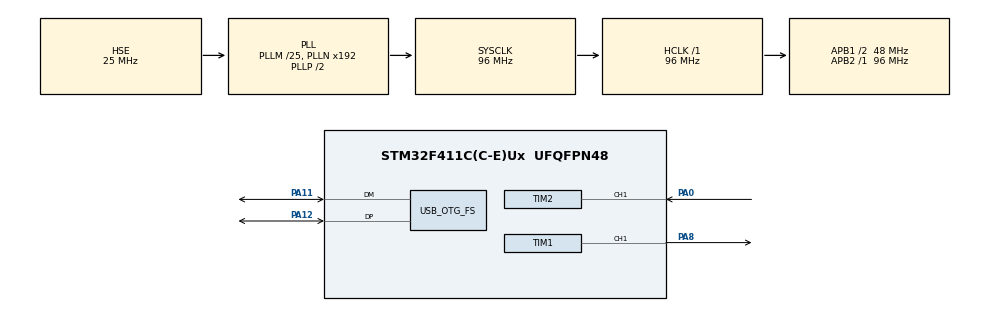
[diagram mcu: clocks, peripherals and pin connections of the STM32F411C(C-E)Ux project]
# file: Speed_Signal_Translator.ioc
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Mcu.Family=STM32F4
Mcu.Name=STM32F411C(C-E)Ux
Mcu.Package=UFQFPN48
NVIC.OTG_FS_IRQn=true\:0\:0\:false\:false\:true\:false\:true\:true
NVIC.PriorityGroup=NVIC_PRIORITYGROUP_4
NVIC.TIM2_IRQn=true\:0\:0\:false\:false\:true\:true\:true\:true
PA0-WKUP.Signal=S_TIM2_CH1_ETR
PA11.Mode=Device_Only
PA11.Signal=USB_OTG_FS_DM
PA12.Mode=Device_Only
PA12.Signal=USB_OTG_FS_DP
PA13.Mode=Serial_Wire
PA13.Signal=SYS_JTMS-SWDIO
PA14.Mode=Serial_Wire
PA14.Signal=SYS_JTCK-SWCLK
PA8.Signal=S_TIM1_CH1
PH0\ -\ OSC_IN.Mode=HSE-External-Oscillator
PH0\ -\ OSC_IN.Signal=RCC_OSC_IN
PH1\ -\ OSC_OUT.Mode=HSE-External-Oscillator
PH1\ -\ OSC_OUT.Signal=RCC_OSC_OUT
ProjectManager.HeapSize=0x200
ProjectManager.StackSize=0x400
ProjectManager.TargetToolchain=CMake
RCC.48MHZClocksFreq_Value=48000000
RCC.AHBFreq_Value=96000000
RCC.APB1CLKDivider=RCC_HCLK_DIV2
RCC.APB1Freq_Value=48000000
RCC.APB1TimFreq_Value=96000000
RCC.APB2Freq_Value=96000000
RCC.APB2TimFreq_Value=96000000
RCC.CortexFreq_Value=96000000
RCC.HCLKFreq_Value=96000000
RCC.HSE_VALUE=25000000
RCC.HSI_VALUE=16000000
RCC.LSE_VALUE=32768
RCC.PLLM=25
RCC.PLLSourceVirtual=RCC_PLLSOURCE_HSE
RCC.SYSCLKFreq_VALUE=96000000
RCC.SYSCLKSource=RCC_SYSCLKSOURCE_PLLCLK
RCC.VCOOutputFreq_Value=192000000
SH.S_TIM1_CH1.0=TIM1_CH1,PWM Generation1 CH1
SH.S_TIM2_CH1_ETR.0=TIM2_CH1,Input_Capture1_from_TI1
TIM1.Channel-PWM\ Generation1\ CH1=TIM_CHANNEL_1
TIM1.Period=4799
TIM2.Channel-Input_Capture1_from_TI1=TIM_CHANNEL_1
TIM2.Prescaler=95
USB_DEVICE.CLASS_NAME_FS=CDC
USB_DEVICE.VirtualMode=Cdc
USB_DEVICE.VirtualModeFS=Cdc_FS
USB_OTG_FS.VirtualMode=Device_Only
VP_TIM1_VS_ClockSourceINT.Mode=Internal
VP_TIM2_VS_ClockSourceINT.Mode=Internal
VP_USB_DEVICE_VS_USB_DEVICE_CDC_FS.Mode=CDC_FS
board=custom

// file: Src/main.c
/* USER CODE BEGIN Header */
/**
 ******************************************************************************
 * @file           : main.c
 * @brief          : STM32F411 USB CDC Sine PWM Controller
 *
 * Project: UTRA Speed Signal Translator
 *
 * Features:
 * - 96 MHz system clock
 * - 48 MHz USB clock
 * - TIM1 CH1 PWM output on PA8
 * - 20 kHz PWM frequency
 * - 0% -> 100% -> 0% sine-shaped duty cycle
 * - 4-second sine period
 * - USB CDC communication
 * - TIM2 Input Capture initialization
 *
 ******************************************************************************
 */
/* USER CODE END Header */

#include "main.h"
#include "usb_device.h"

/* USER CODE BEGIN Includes */
#include "pwm_control.h"
#include "sine_pwm.h"
/* USER CODE END Includes */

TIM_HandleTypeDef htim1;
TIM_HandleTypeDef htim2;

void SystemClock_Config(void);

static void MX_GPIO_Init(void);
static void MX_TIM1_Init(void);
static void MX_TIM2_Init(void);

/**
 * @brief Main program
 * @retval int
 */
int main(void)
{
    HAL_Init();

    /* Configure 96 MHz system clock */
    SystemClock_Config();

    /* Initialize peripherals */
    MX_GPIO_Init();
    MX_TIM1_Init();
    MX_TIM2_Init();
    MX_USB_DEVICE_Init();

    /* USER CODE BEGIN 2 */

    /*
     * Initialize PWM at 20 kHz, 50% duty.
     * TIM1 PWM starts here.
     */
    PWM_Control_Init();

    /*
     * Initialize sine-shaped duty cycle.
     * Set initial duty to 0%.
     */
    Sine_PWM_Init();

    /* USER CODE END 2 */

    /* Infinite loop */
    while (1)
    {

        /* USER CODE BEGIN 3 */

        /*
         * Process incoming USB CDC commands.
         */
        PWM_Control_Process();

        /*
         * Automatically update PWM duty cycle.
         *
         * 0% -> 100% -> 0%
         * Complete cycle: 4 seconds
         * Update interval: 10 milliseconds
         */
        Sine_PWM_Update();

        /* USER CODE END 3 */
    }
}

void SystemClock_Config(void)
{
    RCC_OscInitTypeDef RCC_OscInitStruct = {0};
    RCC_ClkInitTypeDef RCC_ClkInitStruct = {0};

    /* Enable power control clock */
    __HAL_RCC_PWR_CLK_ENABLE();

    /* Voltage regulator scaling */
    __HAL_PWR_VOLTAGESCALING_CONFIG(
        PWR_REGULATOR_VOLTAGE_SCALE1
    );

    /*
     * External HSE crystal = 25 MHz
     *
     * PLLM = 25
     * PLLN = 192
     * PLLP = 2
     * PLLQ = 4
     *
     * SYSCLK = 96 MHz
     * USB clock = 48 MHz
     */

    RCC_OscInitStruct.OscillatorType =
        RCC_OSCILLATORTYPE_HSE;

    RCC_OscInitStruct.HSEState =
        RCC_HSE_ON;

    RCC_OscInitStruct.PLL.PLLState =
        RCC_PLL_ON;

    RCC_OscInitStruct.PLL.PLLSource =
        RCC_PLLSOURCE_HSE;

    RCC_OscInitStruct.PLL.PLLM = 25;
    RCC_OscInitStruct.PLL.PLLN = 192;
    RCC_OscInitStruct.PLL.PLLP = RCC_PLLP_DIV2;
    RCC_OscInitStruct.PLL.PLLQ = 4;

    if (HAL_RCC_OscConfig(&RCC_OscInitStruct)
        != HAL_OK)
    {
        Error_Handler();
    }

    /* Configure bus clocks */

    RCC_ClkInitStruct.ClockType =
        RCC_CLOCKTYPE_HCLK |
        RCC_CLOCKTYPE_SYSCLK |
        RCC_CLOCKTYPE_PCLK1 |
        RCC_CLOCKTYPE_PCLK2;

    RCC_ClkInitStruct.SYSCLKSource =
        RCC_SYSCLKSOURCE_PLLCLK;

    RCC_ClkInitStruct.AHBCLKDivider =
        RCC_SYSCLK_DIV1;

    RCC_ClkInitStruct.APB1CLKDivider =
        RCC_HCLK_DIV2;

    RCC_ClkInitStruct.APB2CLKDivider =
        RCC_HCLK_DIV1;

    /*
     * SYSCLK = 96 MHz
     * HCLK   = 96 MHz
     * PCLK1  = 48 MHz
     * PCLK2  = 96 MHz
     *
     * TIM1 clock = 96 MHz
     * TIM2 clock = 96 MHz
     */

    if (HAL_RCC_ClockConfig(
            &RCC_ClkInitStruct,
            FLASH_LATENCY_3) != HAL_OK)
    {
        Error_Handler();
    }
}

/**
 * @brief TIM1 PWM Initialization
 *
 * TIM1 Channel 1 -> PA8
 *
 * Initial PWM:
 * Frequency = 20 kHz
 * Duty = 50%
 *
 * Sine_PWM_Init() changes duty to 0%.
 */
static void MX_TIM1_Init(void)
{
    TIM_OC_InitTypeDef sConfigOC = {0};
    TIM_MasterConfigTypeDef sMasterConfig = {0};

    /* Enable TIM1 clock */
    __HAL_RCC_TIM1_CLK_ENABLE();

    /*
     * Timer clock = 96 MHz
     *
     * PWM frequency:
     *
     * 96,000,000 / ((0 + 1) * (4799 + 1))
     * = 20,000 Hz
     */

    htim1.Instance = TIM1;

    htim1.Init.Prescaler = 0;

    htim1.Init.CounterMode =
        TIM_COUNTERMODE_UP;

    htim1.Init.Period = 4799;

    htim1.Init.ClockDivision =
        TIM_CLOCKDIVISION_DIV1;

    htim1.Init.RepetitionCounter = 0;

    htim1.Init.AutoReloadPreload =
        TIM_AUTORELOAD_PRELOAD_DISABLE;

    if (HAL_TIM_PWM_Init(&htim1) != HAL_OK)
    {
        Error_Handler();
    }

    /* TIM1 master configuration */

    sMasterConfig.MasterOutputTrigger =
        TIM_TRGO_RESET;

    sMasterConfig.MasterSlaveMode =
        TIM_MASTERSLAVEMODE_DISABLE;

    if (HAL_TIMEx_MasterConfigSynchronization(
            &htim1,
            &sMasterConfig) != HAL_OK)
    {
        Error_Handler();
    }

    /* Configure PWM Channel 1 */

    sConfigOC.OCMode =
        TIM_OCMODE_PWM1;

    sConfigOC.Pulse = 2400;

    sConfigOC.OCPolarity =
        TIM_OCPOLARITY_HIGH;

    sConfigOC.OCNPolarity =
        TIM_OCNPOLARITY_HIGH;

    sConfigOC.OCFastMode =
        TIM_OCFAST_DISABLE;

    sConfigOC.OCIdleState =
        TIM_OCIDLESTATE_RESET;

    sConfigOC.OCNIdleState =
        TIM_OCNIDLESTATE_RESET;

    if (HAL_TIM_PWM_ConfigChannel(
            &htim1,
            &sConfigOC,
            TIM_CHANNEL_1) != HAL_OK)
    {
        Error_Handler();
    }
}

/**
 * @brief TIM2 Input Capture Initialization
 *
 * Reserved for future speed feedback.
 *
 * Timer clock = 96 MHz
 * Prescaler = 95
 * Counter frequency = 1 MHz
 *
 * TIM2 is initialized but capture is not started.
 */
static void MX_TIM2_Init(void)
{
    TIM_IC_InitTypeDef sConfigIC = {0};

    /* Enable TIM2 clock */
    __HAL_RCC_TIM2_CLK_ENABLE();

    htim2.Instance = TIM2;

    htim2.Init.Prescaler = 95;

    htim2.Init.CounterMode =
        TIM_COUNTERMODE_UP;

    htim2.Init.Period =
        0xFFFFFFFFU;

    htim2.Init.ClockDivision =
        TIM_CLOCKDIVISION_DIV1;

    htim2.Init.AutoReloadPreload =
        TIM_AUTORELOAD_PRELOAD_DISABLE;

    if (HAL_TIM_IC_Init(&htim2) != HAL_OK)
    {
        Error_Handler();
    }

    /* Configure TIM2 Channel 1 */

    sConfigIC.ICPolarity =
        TIM_INPUTCHANNELPOLARITY_RISING;

    sConfigIC.ICSelection =
        TIM_ICSELECTION_DIRECTTI;

    sConfigIC.ICPrescaler =
        TIM_ICPSC_DIV1;

    sConfigIC.ICFilter = 0;

    if (HAL_TIM_IC_ConfigChannel(
            &htim2,
            &sConfigIC,
            TIM_CHANNEL_1) != HAL_OK)
    {
        Error_Handler();
    }

    /*
     * Do not start TIM2 Input Capture yet.
     * GPIO and interrupt configuration are still needed.
     */
}

/**
 * @brief GPIO Initialization
 *
 * PA8 = TIM1 Channel 1 PWM output
 */
static void MX_GPIO_Init(void)
{
    GPIO_InitTypeDef GPIO_InitStruct = {0};

    /* Enable GPIOA clock */
    __HAL_RCC_GPIOA_CLK_ENABLE();

    /* Configure PA8 as TIM1_CH1 */

    GPIO_InitStruct.Pin =
        GPIO_PIN_8;

    GPIO_InitStruct.Mode =
        GPIO_MODE_AF_PP;

    GPIO_InitStruct.Pull =
        GPIO_NOPULL;

    GPIO_InitStruct.Speed =
        GPIO_SPEED_FREQ_HIGH;

    GPIO_InitStruct.Alternate =
        GPIO_AF1_TIM1;

    HAL_GPIO_Init(
        GPIOA,
        &GPIO_InitStruct
    );
}

/**
 * @brief Error Handler
 */
void Error_Handler(void)
{
    __disable_irq();

    while (1)
    {
        /* Stay here if initialization fails */
    }
}
